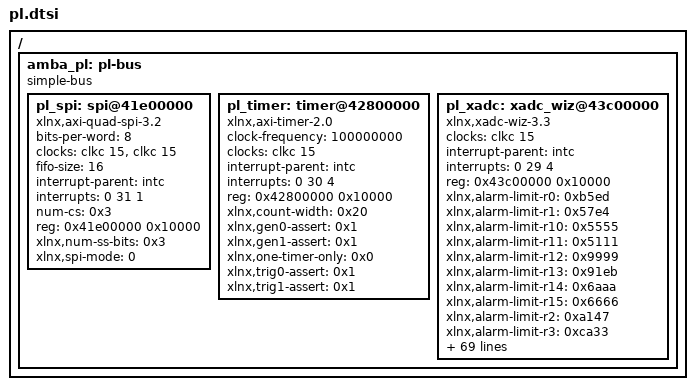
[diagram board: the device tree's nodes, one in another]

/ {
	amba_pl: pl-bus {
		#address-cells = <1>;
		#size-cells = <1>;
		compatible = "simple-bus";
		ranges ;
		pl_spi: spi@41e00000 {
			bits-per-word = <8>;
			clock-names = "ext_spi_clk", "s_axi_aclk";
			clocks = <&clkc 15>, <&clkc 15>;
			compatible = "xlnx,axi-quad-spi-3.2", "xlnx,xps-spi-2.00.a";
			fifo-size = <16>;
			interrupt-names = "ip2intc_irpt";
			interrupt-parent = <&intc>;
			interrupts = <0 31 1>;
			num-cs = <0x3>;
			reg = <0x41e00000 0x10000>;
			xlnx,num-ss-bits = <0x3>;
			xlnx,spi-mode = <0>;
		};
		pl_timer: timer@42800000 {
			clock-frequency = <100000000>;
			clock-names = "s_axi_aclk";
			clocks = <&clkc 15>;
			compatible = "xlnx,axi-timer-2.0", "xlnx,xps-timer-1.00.a";
			interrupt-names = "interrupt";
			interrupt-parent = <&intc>;
			interrupts = <0 30 4>;
			reg = <0x42800000 0x10000>;
			xlnx,count-width = <0x20>;
			xlnx,gen0-assert = <0x1>;
			xlnx,gen1-assert = <0x1>;
			xlnx,one-timer-only = <0x0>;
			xlnx,trig0-assert = <0x1>;
			xlnx,trig1-assert = <0x1>;
		};
		pl_xadc: xadc_wiz@43c00000 {
			clock-names = "s_axi_aclk";
			clocks = <&clkc 15>;
			compatible = "xlnx,xadc-wiz-3.3", "xlnx,axi-xadc-1.00.a";
			interrupt-names = "ip2intc_irpt";
			interrupt-parent = <&intc>;
			interrupts = <0 29 4>;
			reg = <0x43c00000 0x10000>;
			xlnx,alarm-limit-r0 = <0xb5ed>;
			xlnx,alarm-limit-r1 = <0x57e4>;
			xlnx,alarm-limit-r10 = <0x5555>;
			xlnx,alarm-limit-r11 = <0x5111>;
			xlnx,alarm-limit-r12 = <0x9999>;
			xlnx,alarm-limit-r13 = <0x91eb>;
			xlnx,alarm-limit-r14 = <0x6aaa>;
			xlnx,alarm-limit-r15 = <0x6666>;
			xlnx,alarm-limit-r2 = <0xa147>;
			xlnx,alarm-limit-r3 = <0xca33>;
			xlnx,alarm-limit-r4 = <0xa93a>;
			xlnx,alarm-limit-r5 = <0x52c6>;
			xlnx,alarm-limit-r6 = <0x9555>;
			xlnx,alarm-limit-r7 = <0xae4e>;
			xlnx,alarm-limit-r8 = <0x5999>;
			xlnx,alarm-limit-r9 = <0x5111>;
			xlnx,configuration-r0 = <0x0>;
			xlnx,configuration-r1 = <0x21a0>;
			xlnx,configuration-r2 = <0x400>;
			xlnx,dclk-frequency = <0x64>;
			xlnx,external-mux = "none";
			xlnx,external-mux-channel = "VP_VN";
			xlnx,external-muxaddr-enable = <0x0>;
			xlnx,fifo-depth = <0x7>;
			xlnx,has-axi = <0x1>;
			xlnx,has-axi4stream = <0x0>;
			xlnx,has-busy = <0x1>;
			xlnx,has-channel = <0x1>;
			xlnx,has-convst = <0x0>;
			xlnx,has-convstclk = <0x0>;
			xlnx,has-dclk = <0x1>;
			xlnx,has-drp = <0x0>;
			xlnx,has-eoc = <0x1>;
			xlnx,has-eos = <0x1>;
			xlnx,has-external-mux = <0x0>;
			xlnx,has-jtagbusy = <0x0>;
			xlnx,has-jtaglocked = <0x0>;
			xlnx,has-jtagmodified = <0x0>;
			xlnx,has-ot-alarm = <0x1>;
			xlnx,has-reset = <0x0>;
			xlnx,has-temp-bus = <0x0>;
			xlnx,has-user-temp-alarm = <0x1>;
			xlnx,has-vbram-alarm = <0x0>;
			xlnx,has-vccaux-alarm = <0x1>;
			xlnx,has-vccddro-alarm = <0x1>;
			xlnx,has-vccint-alarm = <0x1>;
			xlnx,has-vccpaux-alarm = <0x1>;
			xlnx,has-vccpint-alarm = <0x1>;
			xlnx,has-vn = <0x1>;
			xlnx,has-vp = <0x1>;
			xlnx,include-intr = <0x1>;
			xlnx,sampling-rate = "961538.4615384615";
			xlnx,sequence-r0 = <0x800>;
			xlnx,sequence-r1 = <0xa262>;
			xlnx,sequence-r2 = <0x0>;
			xlnx,sequence-r3 = <0x0>;
			xlnx,sequence-r4 = <0x0>;
			xlnx,sequence-r5 = <0x0>;
			xlnx,sequence-r6 = <0x0>;
			xlnx,sequence-r7 = <0x0>;
			xlnx,sim-file-name = "design";
			xlnx,sim-file-rel-path = "./";
			xlnx,sim-file-sel = "Default";
			xlnx,vaux0 = <0x0>;
			xlnx,vaux1 = <0x1>;
			xlnx,vaux10 = <0x0>;
			xlnx,vaux11 = <0x0>;
			xlnx,vaux12 = <0x0>;
			xlnx,vaux13 = <0x1>;
			xlnx,vaux14 = <0x0>;
			xlnx,vaux15 = <0x1>;
			xlnx,vaux2 = <0x0>;
			xlnx,vaux3 = <0x0>;
			xlnx,vaux4 = <0x0>;
			xlnx,vaux5 = <0x1>;
			xlnx,vaux6 = <0x1>;
			xlnx,vaux7 = <0x0>;
			xlnx,vaux8 = <0x0>;
			xlnx,vaux9 = <0x1>;
		};
	};
};
